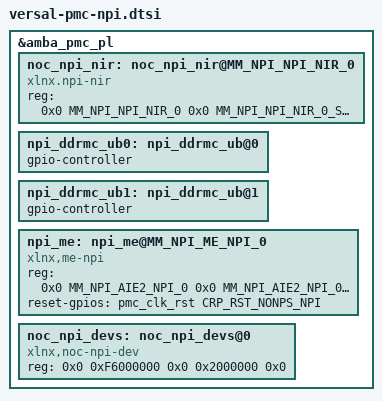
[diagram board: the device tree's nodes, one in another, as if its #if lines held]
/*
 * Versal PMC NPI
 *
 * Copyright (c) 2016, Xilinx Inc
 * All rights reserved.
 *
 * Redistribution and use in source and binary forms, with or without
 * modification, are permitted provided that the following conditions are met:
 *     * Redistributions of source code must retain the above copyright
 *       notice, this list of conditions and the following disclaimer.
 *     * Redistributions in binary form must reproduce the above copyright
 *       notice, this list of conditions and the following disclaimer in the
 *       documentation and/or other materials provided with the distribution.
 *     * Neither the name of the <organization> nor the
 *       names of its contributors may be used to endorse or promote products
 *       derived from this software without specific prior written permission.
 *
 * THIS SOFTWARE IS PROVIDED BY THE COPYRIGHT HOLDERS AND CONTRIBUTORS "AS IS" AND
 * ANY EXPRESS OR IMPLIED WARRANTIES, INCLUDING, BUT NOT LIMITED TO, THE IMPLIED
 * WARRANTIES OF MERCHANTABILITY AND FITNESS FOR A PARTICULAR PURPOSE ARE
 * DISCLAIMED. IN NO EVENT SHALL <COPYRIGHT HOLDER> BE LIABLE FOR ANY
 * DIRECT, INDIRECT, INCIDENTAL, SPECIAL, EXEMPLARY, OR CONSEQUENTIAL DAMAGES
 * (INCLUDING, BUT NOT LIMITED TO, PROCUREMENT OF SUBSTITUTE GOODS OR SERVICES;
 * LOSS OF USE, DATA, OR PROFITS; OR BUSINESS INTERRUPTION) HOWEVER CAUSED AND
 * ON ANY THEORY OF LIABILITY, WHETHER IN CONTRACT, STRICT LIABILITY, OR TORT
 * (INCLUDING NEGLIGENCE OR OTHERWISE) ARISING IN ANY WAY OUT OF THE USE OF THIS
 * SOFTWARE, EVEN IF ADVISED OF THE POSSIBILITY OF SUCH DAMAGE.
 */

#include "versal.dtsh"

#ifdef VERSAL_PSX
	#define COMPAT_DDRMC_UB "xlnx,ddrmc5_ub"
#else
	#define COMPAT_DDRMC_UB "xlnx,versal-ddrmc-ub"
#endif

#define GEN_NMU(N)							\
	npi_noc_nmu_ ## N: npi_noc_nmu_## N@MM_NPI_NOC_NMU_ ## N  {	\
		doc-ignore = <1>;					\
		doc-status = "partial";					\
		doc-comments = "A stub including minimal setup.";	\
		compatible = "xlnx,noc-nmu";				\
		reg = <0x0 MM_NPI_NOC_NMU_ ## N 0x0 MM_NPI_NOC_NMU_ ## N ## _SIZE 0x1>; \
		reset-gpios = <&pmc_clk_rst CRP_RST_NONPS_NPI >;	\
	};

#define GEN_NSU(N)							\
	npi_noc_nsu_ ## N: npi_noc_nsu_## N@MM_NPI_NOC_NSU_ ## N  {	\
		doc-ignore = <1>;					\
		doc-status = "partial";					\
		doc-comments = "A stub including minimal setup.";	\
		compatible = "xlnx,noc-nsu";				\
		reg = <0x0 MM_NPI_NOC_NSU_ ## N 0x0 MM_NPI_NOC_NSU_ ## N ## _SIZE 0x1>; \
		reset-gpios = <&pmc_clk_rst CRP_RST_NONPS_NPI >;	\
	};

#define GEN_NPS(N)							\
	npi_noc_nps_ ## N: npi_noc_nps_## N@MM_NPI_NOC_NPS_ ## N  {	\
		doc-ignore = <1>;					\
		doc-status = "partial";					\
		doc-comments = "A stub including minimal setup.";	\
		compatible = "xlnx,noc-nps";				\
		reg = <0x0 MM_NPI_NOC_NPS_ ## N 0x0 MM_NPI_NOC_NPS_ ## N ## _SIZE 0x1>; \
		reset-gpios = <&pmc_clk_rst CRP_RST_NONPS_NPI >;	\
	};

#define GEN_DDRMC_UB(N)							\
	npi_ddrmc_ub ## N: npi_ddrmc_ub ## N@MM_NPI_DDRMC_UB_ ## N {	\
		doc-limitations = "Only the uB rst is supported";	\
		compatible = COMPAT_DDRMC_UB;				\
		reg = <0x0 MM_NPI_DDRMC_UB_ ## N 0x0			\
			MM_NPI_DDRMC_UB_ ## N ## _SIZE 0x1>;		\
		reset-gpios = <&pmc_clk_rst CRP_RST_NONPS_NPI >;	\
		#gpio-cells = <1>;					\
		gpio-controller;					\
	}

#define GEN_DDRMC_MAIN(N)						\
	npi_ddrmc_main ## N: npi_ddrmc_main ## N@MM_NPI_DDRMC_MAIN_ ## N { \
		doc-limitations = "Just a stub";			\
		compatible = "xlnx,versal-ddrmc-main";			\
		reg = <0x0 MM_NPI_DDRMC_MAIN_ ## N 0x0			\
			MM_NPI_DDRMC_MAIN_ ## N ## _SIZE 0x1>;		\
		reset-gpios = <&pmc_clk_rst CRP_RST_NONPS_NPI >;	\
	}

/* NOC overlaps with UB regs, for the moment we map NOC as lower prio.  */
#define GEN_DDRMC_NOC(N)						\
	npi_ddrmc_noc ## N: npi_ddrmc_noc ## N@MM_NPI_DDRMC_NOC_ ## N { \
		doc-limitations = "Just a stub";			\
		compatible = "xlnx,versal-ddrmc-noc";			\
		reg = <0x0 MM_NPI_DDRMC_NOC_ ## N 0x0			\
			MM_NPI_DDRMC_NOC_ ## N ## _SIZE 0xffffffff>;	\
		reset-gpios = <&pmc_clk_rst CRP_RST_NONPS_NPI >;	\
	}

/*
 * On hardware, DDRMC_XMPU is contained inside DDRMC_NOC so
 * give it higher priority
 */
#define GEN_DDRMC_XMPU(N, addr, offset)						\
	npi_ddrmc_xmpu ## N: npi_ddrmc_xmpu ## N@addr { \
		compatible = "xlnx,versal-ddrmc-xmpu";		\
		reg-extended =	<							\
			&amba_pmc_pl 0x0 (addr + offset) 0x0 0x10000 0x1	\
			&amba 0x0 0x0 0x0 0x80000000 0x0		\
		>;											\
		protected-mr = <&ddr>;						\
		mr-0 = <&amba>;								\
		protected-base = <0x0>;						\
	}

#define GEN_GTY_NPI(N)							\
	npi_gty ## N: npi_gty ## N@MM_NPI_GTY_NPI_SLAVE_ ## N {		\
		doc-limitations = "Just a stub";			\
		compatible = "xlnx,versal-gty-npi";			\
		reg = <0x0 MM_NPI_GTY_NPI_SLAVE_ ## N 0x0		\
			MM_NPI_GTY_NPI_SLAVE_ ## N ## _SIZE 0xffffffff>;\
		reset-gpios = <&pmc_clk_rst CRP_RST_NONPS_NPI >;	\
	}

#define GEN_XPIO_DCI(N)							\
	npi_xpio ## N: npi_xpio ## N@MM_NPI_XPIO_DCI_COMPONENT_ ## N {	\
		doc-limitations = "Just a stub";			\
		compatible = "xlnx,versal-xpio-dci";			\
		reg = <0x0 MM_NPI_XPIO_DCI_COMPONENT_ ## N 0x0		\
			MM_NPI_XPIO_DCI_COMPONENT_ ## N ## _SIZE 0xffffffff>;\
		reset-gpios = <&pmc_clk_rst CRP_RST_NONPS_NPI >;	\
	}

#define GEN_CMT_XPLL(N)							\
	npi_cmt_xpll ## N: npi_cmt_xpll ## N@MM_NPI_CMT_XPLL_ ## N {\
		doc-limitations = "Just a stub";			\
		compatible = "xlnx,versal-cmt-xpll";			\
		reg = <0x0 MM_NPI_CMT_XPLL_ ## N 0x0		\
			MM_NPI_CMT_XPLL_ ## N ## _SIZE 0xffffffff>;	\
		reset-gpios = <&pmc_clk_rst CRP_RST_NONPS_NPI >;	\
	}

#define GEN_CMT_DPLL(N)							\
	npi_cmt_dpll ## N: npi_cmt_dpll ## N@MM_NPI_CMT_DPLL_ ## N {\
		doc-limitations = "Just a stub";			\
		compatible = "xlnx,versal-cmt-dpll";			\
		reg = <0x0 MM_NPI_CMT_DPLL_ ## N 0x0		\
			MM_NPI_CMT_DPLL_ ## N ## _SIZE 0xffffffff>;	\
		reset-gpios = <&pmc_clk_rst CRP_RST_NONPS_NPI >;	\
	}

#define GEN_CMT_MMCM(N)							\
	npi_cmt_mmcm ## N: npi_cmt_mmcm ## N@MM_NPI_CMT_MMCM_ ## N {\
		doc-limitations = "Just a stub";			\
		compatible = "xlnx,versal-cmt-mmcm";			\
		reg = <0x0 MM_NPI_CMT_MMCM_ ## N 0x0		\
			MM_NPI_CMT_MMCM_ ## N ## _SIZE 0xffffffff>;	\
		reset-gpios = <&pmc_clk_rst CRP_RST_NONPS_NPI >;	\
	}

#define GEN_NOC_NCRB(N)							\
	noc_ncrb ## N: noc_ncrb ## N@MM_NPI_NOC_NCRB_ ## N {\
		doc-limitations = "just a stub";			\
		compatible = "xlnx,noc_ncrb";				\
		reg = <0x0 MM_NPI_NOC_NCRB_ ## N 0x0			\
			MM_NPI_NOC_NCRB_ ## N ## _SIZE 0xffffffff>;	\
		reset-gpios = <&pmc_clk_rst CRP_RST_NONPS_NPI>;		\
	}

&amba_pmc_pl {
#ifdef MM_NPI_NPI_NIR_0
	noc_npi_nir: noc_npi_nir@MM_NPI_NPI_NIR_0 {
		compatible="xlnx.npi-nir";
		reg = <0x0 MM_NPI_NPI_NIR_0 0x0 MM_NPI_NPI_NIR_0_SIZE 0x1>;
	};
#endif

	/* DDRMC NPI registers.  */
#ifdef VERSAL_SLAVE_SLR
	npi_ddrmc_ub0: npi_ddrmc_ub@0 {
		gpio-controller;
	};
	npi_ddrmc_ub1: npi_ddrmc_ub@1 {
		gpio-controller;
	};
#else
#include "versal-ddrmc-npi.dtsi"
#ifndef MM_DDRMC_XMPU_OFFSET
#	define MM_DDRMC_XMPU_OFFSET 0x10000
#endif
	GEN_DDRMC_XMPU(0, MM_NPI_DDRMC_NOC_0, MM_DDRMC_XMPU_OFFSET);
#endif

#ifdef MM_NPI_ME_NPI_0
	npi_me: npi_me@MM_NPI_ME_NPI_0 {
		compatible = "xlnx,me-npi";
		reg = <0x0 MM_NPI_ME_NPI_0 0x0 MM_NPI_ME_NPI_0_SIZE 0x1>;
		reset-gpios = <&pmc_clk_rst CRP_RST_NONPS_NPI >;
	};
#endif
#ifdef MM_NPI_AIE2_NPI_0
	npi_me: npi_me@MM_NPI_ME_NPI_0 {
		compatible = "xlnx,me-npi";
		reg = <0x0 MM_NPI_AIE2_NPI_0 0x0 MM_NPI_AIE2_NPI_0_SIZE 0x1>;
		reset-gpios = <&pmc_clk_rst CRP_RST_NONPS_NPI >;
	};
#endif


#ifdef VERSAL_NPI_GENERIC
	noc_npi_devs: noc_npi_devs@0 {
		compatible="xlnx,noc-npi-dev";
		reg = <0x0 0xF6000000 0x0 0x2000000 0x0>;
	};
#endif
};

#if !defined(VERSAL_NPI_GENERIC)
&amba_pmc_pl {
#ifdef VERSAL_VP1202
#include "versal-vp1202-pmc-npi-nxx.dtsi"
#else
#include "versal-pmc-npi-nxx.dtsi"
#endif
};
#endif
